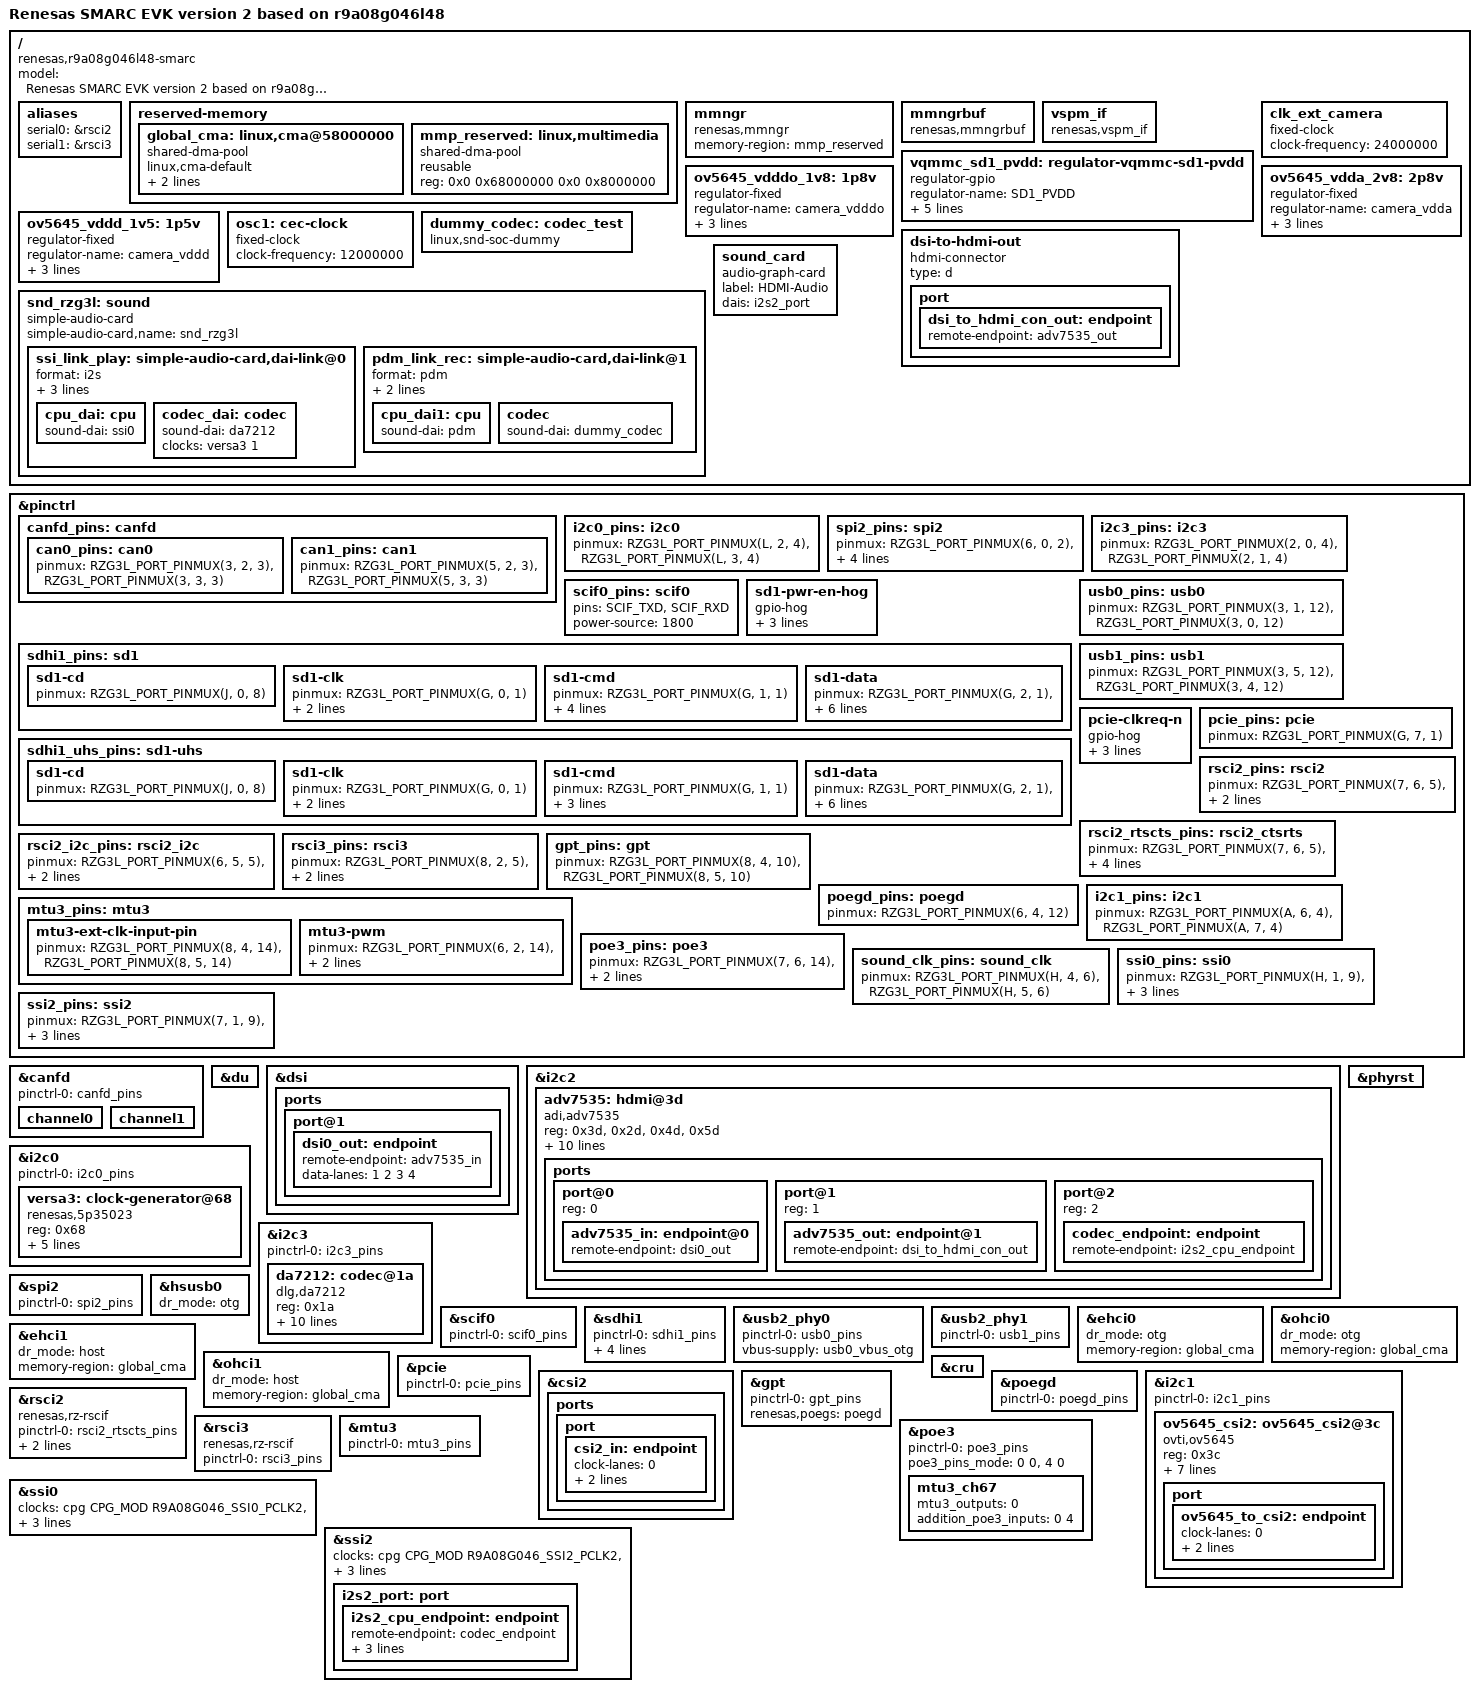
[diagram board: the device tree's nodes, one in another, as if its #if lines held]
// SPDX-License-Identifier: (GPL-2.0-only OR BSD-2-Clause)
/*
 * Device Tree Source for the RZ/G3L SMARC EVK board
 *
 * Copyright (C) 2025 Renesas Electronics Corp.
 */

/dts-v1/;

/* Switch selection settings */
#define SW_SD0_DEV_SEL		0
#define SW_SD2_DEV_SEL		0
#define SW_SDIO_M2E		0
#define SW_DPI_EN		0

/*
 * RSCI2 mode select
 *	0: Disable
 *	1: UART	(default)
 *	2: I2C
 */
#define RSCI2_MODE_SEL		1

/*
 * Enable RSCI3 as SER1 (UART only)
 *	0: Disable SER1 RSCI3
 *	1: Enable (default)
 */
#define SER1_RSCI3_EN		1

/*
* Use to enable POE3 to control Hi-Z state of MTU3
* PWM complementary signals at MTU6_IOC_B-MTU6_IOC_D.
*/
#define POE3_SUPPORT	0

/*
 * MTU3_SUPPORT.
 *	0: GPT and POEG (default)
 *	1: MTU3
 */
#define MTU3_SUPPORT	0

/*
 * SPDIF_SEL - Select pin function between SPDIF and I2C3.
 * 0 - I2C3 is selected		(DA7212 codec control, works with SSI0 audio)
 * 1 - SPDIF is selected	(DA7212 not accessible)
 */
#define SPDIF_SEL		0

/*
 * RS485_SUPPORT - Select pin function of RSCI2 between DE and CTS_RTS
 * 0 - RSCI2_SS_CTS_RTS is selected
 * 1 - RSCI2_DE is selected to support RS485 feature
 */
#define RS485_SUPPORT		1

/*
 * SOSEL_XC - Select the output of the 32kHz-clock oscillator is XC or XBYP
 * 0 - The 32kHz-clock oscillator XC output is selected
 * 1 - The 32kHz-clock oscillator XBYP output is selected (when using external clock)
 */
#define SOSEL_XC		1

#include <dt-bindings/gpio/gpio.h>
#include <dt-bindings/pinctrl/renesas,r9a08g046-pinctrl.h>

/*
 * Display support selection:
 * 0 - disable display selection support
 * 1 - enable display selection support
 * for:
 * - MIPI DSI: RZG3L_SMARC_MIPI_DSI_ENABLE
 * - LVDS: RZG3L_SMARC_LVDS_ENABLE
 * - Display Parallel RGB: also SW_DPI_EN switch config
 */
#define RZG3L_SMARC_MIPI_DSI_ENABLE	1
#define RZG3L_SMARC_LVDS_ENABLE		0

/* MIPI-DSI, LVDS and Display parallel RGB I/F are all input
 * from a single LCDC channel.
 * Only one interface can be enabled at a time.
 */
#if ((RZG3L_SMARC_MIPI_DSI_ENABLE & RZG3L_SMARC_LVDS_ENABLE) || \
(RZG3L_SMARC_MIPI_DSI_ENABLE & SW_DPI_EN) || \
(RZG3L_SMARC_LVDS_ENABLE & SW_DPI_EN))
#error "Only one display output IF can be enabled at a time."
#endif

#include "r9a08g046l48.dtsi"
#include "rzg3l-smarc-som.dtsi"
#include "renesas-smarc2.dtsi"

#if (RZG3L_SMARC_LVDS_ENABLE)
#include "rzg3l-smarc-lvds.dtsi"
#endif

#if (SW_DPI_EN)
#include "rzg3l-smarc-rgb.dtsi"
#endif

/*
 * SSI-DA7212
 *
 * These commands are required when Playback/Capture
 *
 *	amixer -q cset name='Aux Switch' on
 *	amixer -q cset name='Mixin Left Aux Left Switch' on
 *	amixer -q cset name='Mixin Right Aux Right Switch' on
 *	amixer -q cset name='ADC Switch' on
 *	amixer -q cset name='Mixout Right Mixin Right Switch' off
 *	amixer -q cset name='Mixout Left Mixin Left Switch' off
 *	amixer -q cset name='Headphone Volume' 70%
 *	amixer -q cset name='Headphone Switch' on
 *	amixer -q cset name='Mixout Left DAC Left Switch' on
 *	amixer -q cset name='Mixout Right DAC Right Switch' on
 *	amixer -q cset name='DAC Left Source MUX' 'DAI Input Left'
 *	amixer -q cset name='DAC Right Source MUX' 'DAI Input Right'
 *	amixer -q sset 'ADC' 100%
 *	amixer -q sset 'ADC HPF' off
 *	amixer -q sset 'Mic 1 Amp Source MUX' 'MIC_P'
 *	amixer -q sset 'Mic 2 Amp Source MUX' 'MIC_P'
 *	amixer -q sset 'Mixin Left Mic 1' on
 *	amixer -q sset 'Mixin Right Mic 2' on
 *	amixer -q sset 'Mic 1' 90% on
 *	amixer -q sset 'Mic 2' 90% on
 *	amixer -q sset 'Lineout' 80% on
 *	amixer -q set "Headphone" 100% on
 *
 */

/ {
	model = "Renesas SMARC EVK version 2 based on r9a08g046l48";
	compatible = "renesas,r9a08g046l48-smarc", "renesas,r9a08g046l48",
		     "renesas,r9a08g046";

	aliases {
#if (RSCI2_MODE_SEL == 1 && !SW_DPI_EN)
		serial0 = &rsci2;
#elif (RSCI2_MODE_SEL == 2 && !SW_DPI_EN)
		i2c2 = &rsci2;
#endif
#if (SER1_RSCI3_EN)
		serial1 = &rsci3;
#endif
	};

	reserved-memory {
		#address-cells = <2>;
		#size-cells = <2>;
		ranges;

		global_cma: linux,cma@58000000 {
			compatible = "shared-dma-pool";
			linux,cma-default;
			reusable;
			reg = <0x0 0x58000000 0x0 0x10000000>;
		};

		mmp_reserved: linux,multimedia {
			compatible = "shared-dma-pool";
			reusable;
			reg = <0x0 0x68000000 0x0 0x8000000>;
		};
	};

	mmngr {
		compatible = "renesas,mmngr";
		memory-region = <&mmp_reserved>;
	};

	mmngrbuf {
		compatible = "renesas,mmngrbuf";
	};

	vspm_if {
		compatible = "renesas,vspm_if";
	};

#if (!SW_SDIO_M2E)
	vqmmc_sd1_pvdd: regulator-vqmmc-sd1-pvdd {
		compatible = "regulator-gpio";
		regulator-name = "SD1_PVDD";
		regulator-min-microvolt = <1800000>;
		regulator-max-microvolt = <3300000>;
		gpios = <&pinctrl RZG3L_GPIO(J, 1) GPIO_ACTIVE_HIGH>;
		gpios-states = <0>;
		states = <3300000 0>, <1800000 1>;
	};

#else
	vqmmc-wifi-pvdd {
		gpio-hog;
		gpios = <RZG3L_GPIO(J, 1) GPIO_ACTIVE_HIGH>;
		output-high;
		line-name = "wifi1.8";
	};
#endif

	clk_ext_camera: clk_ext_camera {
		compatible = "fixed-clock";
		#clock-cells = <0>;
		clock-frequency = <24000000>;
	};

	ov5645_vdddo_1v8: 1p8v {
		compatible = "regulator-fixed";
		regulator-name = "camera_vdddo";
		regulator-min-microvolt = <1800000>;
		regulator-max-microvolt = <1800000>;
		regulator-always-on;
	};

	ov5645_vdda_2v8: 2p8v {
		compatible = "regulator-fixed";
		regulator-name = "camera_vdda";
		regulator-min-microvolt = <2800000>;
		regulator-max-microvolt = <2800000>;
		regulator-always-on;
	};

	ov5645_vddd_1v5: 1p5v {
		compatible = "regulator-fixed";
		regulator-name = "camera_vddd";
		regulator-min-microvolt = <1500000>;
		regulator-max-microvolt = <1500000>;
		regulator-always-on;
	};

#if (RZG3L_SMARC_MIPI_DSI_ENABLE)
	osc1: cec-clock {
		compatible = "fixed-clock";
		#clock-cells = <0>;
		clock-frequency = <12000000>;
	};

	dsi-to-hdmi-out {
		compatible = "hdmi-connector";
		type = "d";

		port {
			dsi_to_hdmi_con_out: endpoint {
				remote-endpoint = <&adv7535_out>;
			};
		};
	};
#endif

	dummy_codec: codec_test {
		compatible = "linux,snd-soc-dummy";
		#sound-dai-cells = <0>;
	};

	snd_rzg3l: sound {
		compatible = "simple-audio-card";
		simple-audio-card,name = "snd_rzg3l";

#if (!SW_SD2_DEV_SEL && !SPDIF_SEL)
		ssi_link_play: simple-audio-card,dai-link@0 {
			format = "i2s";
			bitclock-master = <&cpu_dai>;
			frame-master = <&cpu_dai>;
			mclk-fs = <256>;

			cpu_dai: cpu {
				sound-dai = <&ssi0>;
			};

			codec_dai: codec {
				sound-dai = <&da7212>;
				clocks = <&versa3 1>;
			};
		};

#elif (!SW_SD2_DEV_SEL && SPDIF_SEL)
		spdif_link: simple-audio-card,dai-link@2 {
			bitclock-master = <&cpu_dai2>;
			frame-master = <&cpu_dai2>;

			cpu_dai2: cpu {
				sound-dai = <&spdif>;
			};

			codec {
				sound-dai = <&dummy_codec>;
			};
		};
#endif

		pdm_link_rec: simple-audio-card,dai-link@1 {
			format = "pdm";
			bitclock-master = <&cpu_dai1>;
			frame-master = <&cpu_dai1>;

			cpu_dai1: cpu {
				sound-dai = <&pdm>;
			};

			codec {
				sound-dai = <&dummy_codec>;
			};
		};
	};

#if (!SW_DPI_EN && RZG3L_SMARC_MIPI_DSI_ENABLE)
	sound_card {
		compatible = "audio-graph-card";
		label = "HDMI-Audio";
		dais = <&i2s2_port>;
	};
#endif
};

&pinctrl {
	canfd_pins: canfd {
		can0_pins: can0 {
			pinmux = <RZG3L_PORT_PINMUX(3, 2, 3)>, /* RX */
				 <RZG3L_PORT_PINMUX(3, 3, 3)>; /* TX */
		};

#if (!SW_DPI_EN)
		can1_pins: can1 {
			pinmux = <RZG3L_PORT_PINMUX(5, 2, 3)>, /* RX */
				 <RZG3L_PORT_PINMUX(5, 3, 3)>; /* TX */
		};
#endif
	};

	i2c0_pins: i2c0 {
		pinmux = <RZG3L_PORT_PINMUX(L, 2, 4)>, /* I2C_PM_CK */
			 <RZG3L_PORT_PINMUX(L, 3, 4)>; /* I2C_PM_DAT */
	};

#if (!SW_DPI_EN && !MTU3_SUPPORT)
	spi2_pins: spi2 {
		pinmux = <RZG3L_PORT_PINMUX(6, 0, 2)>, /* MISO */
			 <RZG3L_PORT_PINMUX(6, 1, 2)>, /* MOSI */
			 <RZG3L_PORT_PINMUX(6, 2, 2)>, /* SCK */
			 <RZG3L_PORT_PINMUX(6, 3, 2)>; /* SSLA */
			 power-source = <1800>;
	};
#endif

#if (!SPDIF_SEL)
	i2c3_pins: i2c3 {
		pinmux = <RZG3L_PORT_PINMUX(2, 0, 4)>, /* SCL */
			 <RZG3L_PORT_PINMUX(2, 1, 4)>; /* SDA */
	};
#endif

	scif0_pins: scif0 {
		pins = "SCIF_TXD", "SCIF_RXD";
		power-source = <1800>;
	};

#if (!SW_SDIO_M2E)
	sd1-pwr-en-hog {
		gpio-hog;
		gpios = <RZG3L_GPIO(J, 2) GPIO_ACTIVE_HIGH>;
		output-high;
		line-name = "sd1_pwr_en";
	};
#endif

	sdhi1_pins: sd1 {
		sd1-cd {
			pinmux = <RZG3L_PORT_PINMUX(J, 0, 8)>; /* SD1_CD */
		};

		sd1-clk {
			pinmux = <RZG3L_PORT_PINMUX(G, 0, 1)>; /* SD1_CLK */
			power-source = <3300>;
			renesas,sd_ch1_poc;
		};

		sd1-cmd {
			pinmux = <RZG3L_PORT_PINMUX(G, 1, 1)>; /* SD1_CMD */
			input-enable;
			power-source = <3300>;
			renesas,sd_ch1_poc;
			bias-pull-up;
		};

		sd1-data {
			pinmux = <RZG3L_PORT_PINMUX(G, 2, 1)>, /* SD1_DAT0 */
				 <RZG3L_PORT_PINMUX(G, 3, 1)>, /* SD1_DAT1 */
				 <RZG3L_PORT_PINMUX(G, 4, 1)>, /* SD1_DAT2 */
				 <RZG3L_PORT_PINMUX(G, 5, 1)>; /* SD1_DAT3 */
			input-enable;
			power-source = <3300>;
			renesas,sd_ch1_poc;
		};
	};

	sdhi1_uhs_pins: sd1-uhs {
		sd1-cd {
			pinmux = <RZG3L_PORT_PINMUX(J, 0, 8)>; /* SD1_CD */
		};

		sd1-clk {
			pinmux = <RZG3L_PORT_PINMUX(G, 0, 1)>; /* SD1_CLK */
			power-source = <1800>;
			renesas,sd_ch1_poc;
		};

		sd1-cmd {
			pinmux = <RZG3L_PORT_PINMUX(G, 1, 1)>; /* SD1_CMD */
			input-enable;
			power-source = <1800>;
			renesas,sd_ch1_poc;
		};

		sd1-data {
			pinmux = <RZG3L_PORT_PINMUX(G, 2, 1)>, /* SD1_DAT0 */
				 <RZG3L_PORT_PINMUX(G, 3, 1)>, /* SD1_DAT1 */
				 <RZG3L_PORT_PINMUX(G, 4, 1)>, /* SD1_DAT2 */
				 <RZG3L_PORT_PINMUX(G, 5, 1)>; /* SD1_DAT3 */
			input-enable;
			power-source = <1800>;
			renesas,sd_ch1_poc;
		};
	};

	usb0_pins: usb0 {
		pinmux = <RZG3L_PORT_PINMUX(3, 1, 12)>, /* VBUS */
			 <RZG3L_PORT_PINMUX(3, 0, 12)>; /* OVC */
	};

	usb1_pins: usb1 {
		pinmux = <RZG3L_PORT_PINMUX(3, 5, 12)>, /* VBUS */
			 <RZG3L_PORT_PINMUX(3, 4, 12)>; /* OVC */
	};

	pcie-clkreq-n {
		gpio-hog;
		gpios = <RZG3L_GPIO(G, 6) GPIO_ACTIVE_HIGH>;
		output-low;
		line-name = "pcie_clkreq_n";
	};

	pcie_pins: pcie {
		pinmux = <RZG3L_PORT_PINMUX(G, 7, 1)>; /* PCIE_RST_OUT# */
	};

#if (RSCI2_MODE_SEL && !SW_DPI_EN)
	rsci2_pins: rsci2 {
		pinmux = <RZG3L_PORT_PINMUX(7, 6, 5)>, /* RSCI2_RXD_MISO_SCL */
			 <RZG3L_PORT_PINMUX(7, 7, 5)>; /* RSCI2_TXD_MOSI_SDA */
		bias-pull-up;
	};

	rsci2_rtscts_pins: rsci2_ctsrts {
		pinmux = <RZG3L_PORT_PINMUX(7, 6, 5)>, /* RSCI2_RXD_MISO_SCL */
			 <RZG3L_PORT_PINMUX(7, 7, 5)>, /* RSCI2_TXD_MOSI_SDA */
			 <RZG3L_PORT_PINMUX(8, 0, 6)>, /* RSCI2_CTS */
#if (!RS485_SUPPORT)
			 <RZG3L_PORT_PINMUX(8, 1, 5)>; /* RSCI2_SS_CTS_RTS */
#else
			 <RZG3L_PORT_PINMUX(8, 1, 6)>; /* RSCI2_DE */
#endif
		bias-pull-up;
	};

	rsci2_i2c_pins: rsci2_i2c {
		pinmux = <RZG3L_PORT_PINMUX(6, 5, 5)>, /* RSCI2_RXD_MISO_SCL */
			 <RZG3L_PORT_PINMUX(6, 6, 5)>; /* RSCI2_TXD_MOSI_SDA */
		bias-pull-up;
	};
#endif

#if (SER1_RSCI3_EN && !SW_DPI_EN)
	rsci3_pins: rsci3 {
		pinmux = <RZG3L_PORT_PINMUX(8, 2, 5)>, /* RSCI3_RXD_MISO_SCL */
			 <RZG3L_PORT_PINMUX(8, 3, 5)>; /* RSCI3_TXD_MOSI_SDA */
		bias-pull-up;
	};
#endif

#if (!SW_DPI_EN && !MTU3_SUPPORT)
	gpt_pins: gpt {
		pinmux = <RZG3L_PORT_PINMUX(8, 4, 10)>, /* GTIOC4A - GPIO13 - PMOD1_3A pin 10 */
			 <RZG3L_PORT_PINMUX(8, 5, 10)>; /* GTIOC4B - GPIO10 - PMOD1_3A pin 7 */
	};

	poegd_pins: poegd {
		pinmux = <RZG3L_PORT_PINMUX(6, 4, 12)>; /* GTERGD - GPIO6 - PMOD0-2A pin 9 */
	};
#endif

	i2c1_pins: i2c1 {
		pinmux = <RZG3L_PORT_PINMUX(A, 6, 4)>, /* I2C1_SCL */
			 <RZG3L_PORT_PINMUX(A, 7, 4)>; /* I2C1_SDA */
	};

#if (!SW_DPI_EN && MTU3_SUPPORT)
	mtu3_pins: mtu3 {
		mtu3-ext-clk-input-pin {
			pinmux = <RZG3L_PORT_PINMUX(8, 4, 14)>, /* MTU_CLK_C */
				 <RZG3L_PORT_PINMUX(8, 5, 14)>; /* MTU_CLK_D */
		};

		mtu3-pwm {
			pinmux = <RZG3L_PORT_PINMUX(6, 2, 14)>, /* MTU6_IOC_B */
				 <RZG3L_PORT_PINMUX(6, 3, 14)>, /* MTU6_IOC_C */
				 <RZG3L_PORT_PINMUX(6, 4, 14)>; /* MTU6_IOC_D */
		};
	};
#endif

#if (POE3_SUPPORT && !SW_DPI_EN && !RSCI2_MODE_SEL)
	poe3_pins: poe3 {
		pinmux = <RZG3L_PORT_PINMUX(7, 6, 14)>, /* MTU_POE0# */
			 <RZG3L_PORT_PINMUX(7, 7, 14)>; /* MTU_POE4# */
		bias-pull-up;
	};
#endif

#if (!SW_SD2_DEV_SEL)
	sound_clk_pins: sound_clk {
		pinmux = <RZG3L_PORT_PINMUX(H, 4, 6)>, /* AUDIO_CLKB */
			 <RZG3L_PORT_PINMUX(H, 5, 6)>; /* AUDIO_CLKC*/
	};

	ssi0_pins: ssi0 {
		pinmux = <RZG3L_PORT_PINMUX(H, 1, 9)>, /* BCK */
			 <RZG3L_PORT_PINMUX(H, 2, 9)>, /* RCK */
			 <RZG3L_PORT_PINMUX(H, 3, 9)>, /* TXD */
			 <RZG3L_PORT_PINMUX(H, 0, 9)>; /* RXD */
	};
#endif

#if (!SW_DPI_EN && RZG3L_SMARC_MIPI_DSI_ENABLE)
	ssi2_pins: ssi2 {
		pinmux = <RZG3L_PORT_PINMUX(7, 1, 9)>, /* BCK */
			 <RZG3L_PORT_PINMUX(7, 2, 9)>, /* RCK */
			 <RZG3L_PORT_PINMUX(7, 3, 9)>, /* TXD */
			 <RZG3L_PORT_PINMUX(7, 0, 9)>; /* RXD */
	};
#endif
};

&canfd {
	pinctrl-0 = <&canfd_pins>;
	pinctrl-names = "default";

	channel0 {
		status = "okay";
	};

#if (!SW_DPI_EN)
	channel1 {
		status = "okay";
	};
#endif
};

#if (RZG3L_SMARC_MIPI_DSI_ENABLE)
&du {
	status = "okay";
};

&dsi {
	status = "okay";

	ports {
		port@1 {
			dsi0_out: endpoint {
				remote-endpoint = <&adv7535_in>;
				data-lanes = <1 2 3 4>;
			};
		};
	};
};

&i2c2 {
	adv7535: hdmi@3d {
		compatible = "adi,adv7535";
		reg = <0x3d>, <0x2d>, <0x4d>, <0x5d>;
		reg-names = "main", "cec", "edid", "packet";

		interrupts-extended = <&pinctrl RZG3L_GPIO(K, 3) IRQ_TYPE_EDGE_FALLING>;
		clocks = <&osc1>;
		clock-names = "cec";
		avdd-supply = <&reg_1p8v>;
		dvdd-supply = <&reg_1p8v>;
		pvdd-supply = <&reg_1p8v>;
		a2vdd-supply = <&reg_1p8v>;
		v3p3-supply = <&reg_3p3v>;
		v1p2-supply = <&reg_1p8v>;

		adi,dsi-lanes = <4>;

		ports {
			#address-cells = <1>;
			#size-cells = <0>;

			port@0 {
				reg = <0>;
				adv7535_in: endpoint@0 {
					remote-endpoint = <&dsi0_out>;
				};
			};

			port@1 {
				reg = <1>;
				adv7535_out: endpoint@1 {
					remote-endpoint = <&dsi_to_hdmi_con_out>;
				};
			};

			port@2 {
				reg = <2>;
				codec_endpoint: endpoint {
					remote-endpoint = <&i2s2_cpu_endpoint>;
				};
			};
		};
	};
};
#endif

&i2c0 {
	pinctrl-0 = <&i2c0_pins>;
	pinctrl-names = "default";

	status = "okay";

	versa3: clock-generator@68 {
		compatible = "renesas,5p35023";
		reg = <0x68>;
		#clock-cells = <1>;
		clocks = <&x2_clk>;

		assigned-clocks = <&versa3 0>, <&versa3 1>,
				  <&versa3 2>, <&versa3 3>,
				  <&versa3 4>, <&versa3 5>;
		assigned-clock-rates = <24000000>, <12288000>,
				       <11289600>, <12288000>,
				       <25000000>, <25000000>;
	};
};

#if (!SPDIF_SEL)
&i2c3 {
	pinctrl-0 = <&i2c3_pins>;
	pinctrl-names = "default";

	status = "okay";

	da7212: codec@1a {
		compatible = "dlg,da7212";
		reg = <0x1a>;

		clocks = <&versa3 1>;
		clock-names = "mclk";

		#sound-dai-cells = <0>;

		dlg,micbias1-lvl = <2500>;
		dlg,micbias2-lvl = <2500>;
		dlg,dmic-data-sel = "lrise_rfall";
		dlg,dmic-samplephase = "between_clkedge";
		dlg,dmic-clkrate = <3000000>;

		VDDA-supply = <&reg_1p8v>;
		VDDSP-supply = <&reg_3p3v>;
		VDDMIC-supply = <&reg_3p3v>;
		VDDIO-supply = <&reg_1p8v>;
	};
};
#endif

#if (!SW_DPI_EN && !MTU3_SUPPORT)
&spi2 {
	pinctrl-0 = <&spi2_pins>;
	pinctrl-names = "default";

	status = "okay";
};
#endif

&scif0 {
	pinctrl-0 = <&scif0_pins>;
	pinctrl-names = "default";
	status = "okay";
};

#if (!SW_SDIO_M2E)
&sdhi1 {
	pinctrl-0 = <&sdhi1_pins>;
	pinctrl-1 = <&sdhi1_uhs_pins>;
	pinctrl-names = "default", "state_uhs";

	vmmc-supply = <&reg_3p3v>;
	vqmmc-supply = <&vqmmc_sd1_pvdd>;

	max-frequency = <300000000>;
};
#else
&sdhi1 {
	pinctrl-0 = <&sdhi1_uhs_pins>;
	pinctrl-names = "default";

	vmmc-supply = <&reg_3p3v>;
	vqmmc-supply = <&reg_1p8v>;

	max-frequency = <300000000>;

	non-removable;
	cap-power-off-card;
	#address-cells = <1>;
	#size-cells = <0>;

	brcmf: bcrmf@1 {
		reg = <1>;
		compatible = "brcm,bcm4329-fmac";
	};
};
#endif

&phyrst {
	status = "okay";
};

&usb2_phy0 {
	pinctrl-0 = <&usb0_pins>;
	pinctrl-names = "default";

	vbus-supply = <&usb0_vbus_otg>;
	status = "okay";
};

&usb2_phy1 {
	pinctrl-0 = <&usb1_pins>;
	pinctrl-names = "default";

	status = "okay";
};

&ehci0 {
	dr_mode = "otg";
	status = "okay";

	memory-region = <&global_cma>;
};

&ohci0 {
	dr_mode = "otg";
	status = "okay";

	memory-region = <&global_cma>;
};

&hsusb0 {
	dr_mode = "otg";
	status = "okay";
};

&ehci1 {
	dr_mode = "host";
	status = "okay";

	memory-region = <&global_cma>;
};

&ohci1 {
	dr_mode = "host";
	status = "okay";

	memory-region = <&global_cma>;
};

&pcie {
	pinctrl-0 = <&pcie_pins>;
	pinctrl-names = "default";
	status = "okay";
};

&cru {
	status = "okay";
};

&csi2 {
	status = "okay";

	ports {
		 port {
			csi2_in: endpoint {
				clock-lanes = <0>;
				data-lanes = <1 2>;
				remote-endpoint = <&ov5645_to_csi2>;
			};
		};
	};
};

#if (!SW_DPI_EN && !MTU3_SUPPORT)
&gpt {
	pinctrl-0 = <&gpt_pins>;
	pinctrl-names = "default";
	renesas,poegs = <&poegd>;
	status = "okay";
};

&poegd {
	pinctrl-0 = <&poegd_pins>;
	pinctrl-names = "default";
	status = "okay";
};
#endif

&i2c1 {
	pinctrl-0 = <&i2c1_pins>;
	pinctrl-names = "default";

	status = "okay";

	ov5645_csi2: ov5645_csi2@3c {
		compatible = "ovti,ov5645";
		reg = <0x3c>;
		clock-names = "xclk";
		clocks = <&clk_ext_camera>;
		clock-frequency = <24000000>;
		vdddo-supply = <&ov5645_vdddo_1v8>;
		vdda-supply = <&ov5645_vdda_2v8>;
		vddd-supply = <&ov5645_vddd_1v5>;
		enable-gpios = <&pinctrl RZG3L_GPIO(M, 6) GPIO_ACTIVE_HIGH>; /* CSI1_PWDNB */
		reset-gpios  = <&pinctrl RZG3L_GPIO(M, 7) GPIO_ACTIVE_LOW>;  /* CSI1_RESET */

		port {
			ov5645_to_csi2: endpoint {
				clock-lanes = <0>;
				data-lanes = <1 2>;
				remote-endpoint = <&csi2_in>;
			};
		};
	};
};

#if (RSCI2_MODE_SEL == 1 && !SW_DPI_EN)
&rsci2 {
	compatible = "renesas,rz-rscif";
	pinctrl-0 = <&rsci2_rtscts_pins>;
	pinctrl-names = "default";
#if (!RS485_SUPPORT)
	uart-has-rtscts;
#else
	linux,rs485-enabled-at-boot-time;
	rs485-rts-delay = <1 1>;
#endif
	status = "okay";
};
#elif (RSCI2_MODE_SEL == 2 && !SW_DPI_EN)
&rsci2 {
	compatible = "renesas,rz-rsci-i2c";
	pinctrl-0 = <&rsci2_i2c_pins>;
	pinctrl-names = "default";
	status = "okay";
};
#endif

#if (SER1_RSCI3_EN && !SW_DPI_EN)
&rsci3 {
	compatible = "renesas,rz-rscif";
	pinctrl-0 = <&rsci3_pins>;
	pinctrl-names = "default";
	status = "okay";
};
#endif

#if (!SW_DPI_EN && MTU3_SUPPORT)
&mtu3 {
	pinctrl-0 = <&mtu3_pins>;
	pinctrl-names = "default";
	status = "okay";
};
#endif

#if (POE3_SUPPORT && !SW_DPI_EN && !RSCI2_MODE_SEL)
&poe3 {
	pinctrl-0 = <&poe3_pins>;
	pinctrl-names = "default";
	poe3_pins_mode = <0 0>, <4 0>;
	status = "okay";
	mtu3_ch67 {
	       mtu3_outputs = <0>; /* MTU6_IOC_B-MTU6_IOC_D */
	       addition_poe3_inputs = <0 4>;
	};
};
#endif

#if (SW_SD2_DEV_SEL)
&sdhi2 {
	pinctrl-0 = <&sdhi2_pins>;
	pinctrl-1 = <&sdhi2_pins_uhs>;
	pinctrl-names = "default", "state_uhs";
	vmmc-supply = <&reg_3p3v>;
	vqmmc-supply = <&vqmmc_sd2_pvdd>;
	bus-width = <4>;
	sd-uhs-sdr50;
	sd-uhs-sdr104;
	max-frequency = <300000000>;
	status = "okay";
};
#else
&ssi0 {
	clocks = <&cpg CPG_MOD R9A08G046_SSI0_PCLK2>,
		 <&cpg CPG_MOD R9A08G046_SSI0_PCLK_SFR>,
		 <&versa3 2>, <&versa3 3>;
	pinctrl-names = "default";
	pinctrl-0 = <&sound_clk_pins>, <&ssi0_pins>;

	status = "okay";
};
#endif

#if (!SW_DPI_EN && RZG3L_SMARC_MIPI_DSI_ENABLE)
&ssi2 {
	clocks = <&cpg CPG_MOD R9A08G046_SSI2_PCLK2>,
		 <&cpg CPG_MOD R9A08G046_SSI2_PCLK_SFR>,
		 <&versa3 2>, <&versa3 3>;
	pinctrl-0 = <&ssi2_pins>;
	pinctrl-names = "default";

	status = "okay";

	i2s2_port: port {
		i2s2_cpu_endpoint: endpoint {
			remote-endpoint = <&codec_endpoint>;
			dai-format = "i2s";

			bitclock-master = <&i2s2_cpu_endpoint>;
			frame-master = <&i2s2_cpu_endpoint>;
		};
	};
};
#endif
